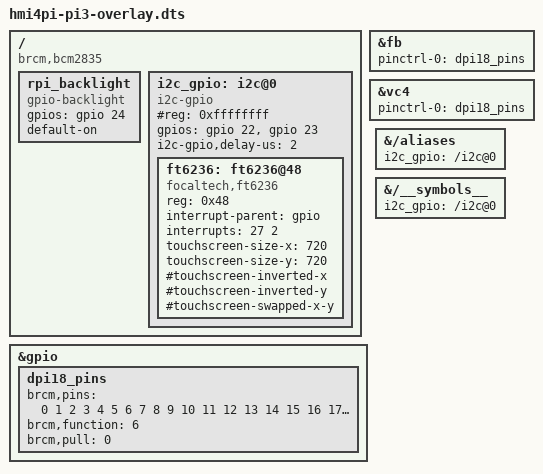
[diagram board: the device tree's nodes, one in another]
/*
 * Device Tree overlay for MakerLAB TFT 4.0" capacitive touch screen
 *
 */

/dts-v1/;
/plugin/;
/ {
	compatible = "brcm,bcm2835", "brcm,bcm2708", "brcm,bcm2709";

	fragment@0 {
		target = <&fb>;
		__overlay__ {
			pinctrl-names = "default";
			pinctrl-0 = <&dpi18_pins>;
		};
	};

	fragment@1 {
		target = <&vc4>;
		__overlay__ {
			pinctrl-names = "default";
			pinctrl-0 = <&dpi18_pins>;
		};
	};

	fragment@2 {
		target = <&gpio>;
		__overlay__ {
			dpi18_pins: dpi18_pins {
				brcm,pins = <0 1 2 3 4 5 6 7 8 9 10 11
					     12 13 14 15 16 17 18 19 20
					     21>;
				brcm,function = <6>; /* alt2 */
				brcm,pull = <0>; /* no pull */
			};
		};
	};

	fragment@3 {
		target-path = "/";
		__overlay__ {
			rpi_backlight: rpi_backlight {
				compatible = "gpio-backlight";
				gpios = <&gpio 24 0>;
				default-on;
			};
		};
	};

	fragment@4 {
		target-path = "/";

		__overlay__ {
			i2c_gpio: i2c@0 {
				#reg = <0xffffffff>;
				compatible = "i2c-gpio";
				gpios = <&gpio 22 0 /* sda */
					 &gpio 23 0 /* scl */
					>;
				i2c-gpio,delay-us = <2>;        /* ~100 kHz */
				#address-cells = <1>;
				#size-cells = <0>;
			};
		};
	};

	fragment@5 {
		target-path = "/aliases";
		__overlay__ {
			i2c_gpio = "/i2c@0";
		};
	};

	fragment@6 {
		target-path = "/__symbols__";
		__overlay__ {
			i2c_gpio = "/i2c@0";
		};
	};

	fragment@7 {
		target = <&i2c_gpio>;
		__overlay__ {
			/* needed to avoid dtc warning */
			#address-cells = <1>;
			#size-cells = <0>;

                        ft6236: ft6236@48 {
                                compatible = "focaltech,ft6236";
                                reg = <0x48>;

                                interrupt-parent = <&gpio>;
                                interrupts = <27 2>;
                                touchscreen-size-x = <720>;
                                touchscreen-size-y = <720>;
				#touchscreen-inverted-x;
				#touchscreen-inverted-y;
				#touchscreen-swapped-x-y;
			};
		};
	};

	__overrides__ {
                touch-sizex = <&ft6236>,"touchscreen-size-x?";
                touch-sizey = <&ft6236>,"touchscreen-size-y?";
                touch-invx  = <&ft6236>,"touchscreen-inverted-x?";
                touch-invy  = <&ft6236>,"touchscreen-inverted-y?";
                touch-swapxy = <&ft6236>,"touchscreen-swapped-x-y?";
	};
};
